# ESP32S31_RADIO register map
Vendor: Espressif; Series: ESP32-S31; File version: 3.52
Registers are 32-bit, read-write, no defined reset value unless marked. A register's access mark holds for its fields unless they carry their own. Offsets are from the block's base; [hi:lo] are bit positions; 'fields as' and 'values as' point back to an identical list.

## PHY_AGC_RECOVERED_GAPS — Sparse AGC words absent from the public platform PAC.
Base 0x20107000
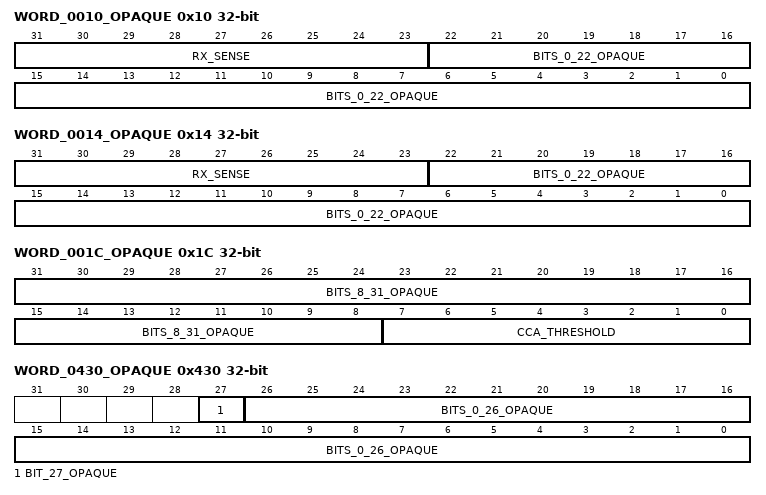
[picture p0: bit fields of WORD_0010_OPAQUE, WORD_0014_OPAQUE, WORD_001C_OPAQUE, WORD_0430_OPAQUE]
0x10 WORD_0010_OPAQUE — Opaque: meaning not established. Read-modify-written by complete phy_rx_sense_set and saved/restored by complete phy_dig_reg_backup.
  [31:23] RX_SENSE — Project-assigned name. Receive-sensitivity setting complete phy_rx_sense_set publishes.
  [22:0] BITS_0_22_OPAQUE — Opaque: meaning not established. Observed source use; the individual hardware meaning is unknown.
0x14 WORD_0014_OPAQUE — Opaque: meaning not established. Read-modify-written by complete phy_rx_sense_set and saved/restored by complete phy_dig_reg_backup.
  fields as WORD_0010_OPAQUE
0x1C WORD_001C_OPAQUE — Opaque: meaning not established. Read and written by complete CCA accessors and saved/restored by complete phy_dig_reg_backup.
  [31:8] BITS_8_31_OPAQUE — Opaque: meaning not established. Observed source use; the individual hardware meaning is unknown.
  [7:0] CCA_THRESHOLD — Project-assigned name. Signed clear-channel-assessment threshold that complete phy_set_cca publishes (0xbf, -65, by default) and complete phy_get_cca returns.
0x50 WORD_0050_OPAQUE access not given — Opaque: meaning not established. Complete phy_get_noise_floor reads this word; hardware access semantics remain unknown.
  [9:0] NOISE_FLOOR — Project-assigned name. Ten-bit noise floor that complete phy_get_noise_floor returns sign-extended as a negative value.
0x6C WORD_006C_OPAQUE access not given — Opaque: meaning not established. Complete phy_get_rssi reads this word; hardware access semantics remain unknown.
  [15:8] RSSI_ABOVE_NOISE_FLOOR — Project-assigned name. Received signal strength above the noise floor: complete phy_get_rssi adds it to the noise floor shifted right by two.
0x74 WORD_0074_OPAQUE — Opaque: meaning not established. Complete phy_chan_filt_set read-modify-writes this word and complete phy_dig_reg_backup saves/restores it.
  [31:0] BITS_0_31_OPAQUE — Opaque: meaning not established. Observed source use; the individual hardware meaning is unknown.
0xCC WORD_00CC_OPAQUE — Opaque: meaning not established. Complete phy_dig_reg_backup saves and restores this word; all field semantics remain unknown.
  fields as WORD_0074_OPAQUE
0xF4 WORD_00F4_OPAQUE — Opaque: meaning not established. Complete phy_wifi_rifs_mode_en read-modify-writes bit zero; all other fields remain unknown.
  [0] RIFS_MODE_ENABLE — Project-assigned name. Reduced-interframe-space receive mode enable that complete phy_wifi_rifs_mode_en publishes.
0x108 WORD_0108_OPAQUE — Opaque: meaning not established. Complete phy_rx_sense_set sets bit nine when the requested sensitivity is zero and clears it otherwise; complete phy_dig_reg_backup saves and restores the word. Field semantics remain unknown.
  fields as WORD_0074_OPAQUE
0x430 WORD_0430_OPAQUE — Opaque: meaning not established. Complete phy_bb_cfo_cfg replaces this word and independently read-modify-writes bit 27; the hardware field meaning remains unknown.
  [27] BIT_27_OPAQUE — Opaque: meaning not established.
  [26:0] BITS_0_26_OPAQUE — Opaque: meaning not established. Observed source use; the individual hardware meaning is unknown.
0x434 WORD_0434_OPAQUE — Opaque: meaning not established. Complete phy_bb_cfo_cfg reads and replaces this word; individual hardware fields remain unnamed.
  [26:0] BITS_0_26_OPAQUE — Opaque: meaning not established. Observed source use; the individual hardware meaning is unknown.
0x438 WORD_0438_OPAQUE — Opaque: meaning not established. Complete phy_bb_cfo_cfg reads and replaces this word; individual hardware fields remain unnamed.
  [11:0] BITS_0_11_OPAQUE — Opaque: meaning not established. Observed source use; the individual hardware meaning is unknown.
